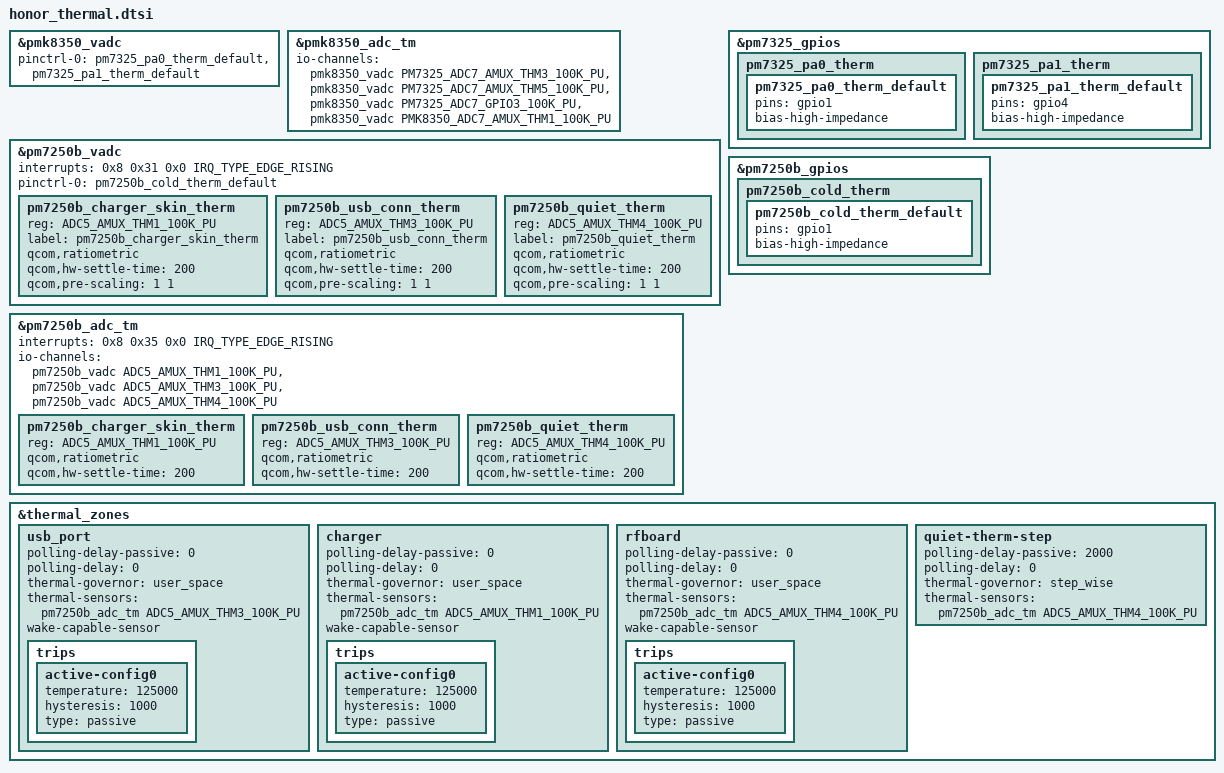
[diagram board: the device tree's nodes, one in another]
&pmk8350_vadc {
	pinctrl-names = "default";
	pinctrl-0 = <&pm7325_pa0_therm_default
				&pm7325_pa1_therm_default>;
	/delete-node/ pm8350b_quiet_therm;
	/delete-node/ pm8350b_usb_conn_therm;
	/delete-node/ pm8350b_chg_skin_therm;
};

&pmk8350_adc_tm {
	io-channels = <&pmk8350_vadc PM7325_ADC7_AMUX_THM3_100K_PU>,
			<&pmk8350_vadc PM7325_ADC7_AMUX_THM5_100K_PU>,
			<&pmk8350_vadc PM7325_ADC7_GPIO3_100K_PU>,
			<&pmk8350_vadc PMK8350_ADC7_AMUX_THM1_100K_PU>;

	/delete-node/ pm8350b_quiet_therm;
	/delete-node/ pm8350b_usb_conn_therm;
	/delete-node/ pm8350b_chg_skin_therm;
};

&pm7250b_vadc {
	interrupts = <0x8 0x31 0x0 IRQ_TYPE_EDGE_RISING>;
	pinctrl-names = "default";
	pinctrl-0 = <&pm7250b_cold_therm_default>;

	pm7250b_charger_skin_therm {
		reg = <ADC5_AMUX_THM1_100K_PU>;
		label = "pm7250b_charger_skin_therm";
		qcom,ratiometric;
		qcom,hw-settle-time = <200>;
		qcom,pre-scaling = <1 1>;
	};

	pm7250b_usb_conn_therm {
		reg = <ADC5_AMUX_THM3_100K_PU>;
		label = "pm7250b_usb_conn_therm";
		qcom,ratiometric;
		qcom,hw-settle-time = <200>;
		qcom,pre-scaling = <1 1>;
	};

	pm7250b_quiet_therm {
		reg = <ADC5_AMUX_THM4_100K_PU>;
		label = "pm7250b_quiet_therm";
		qcom,ratiometric;
		qcom,hw-settle-time = <200>;
		qcom,pre-scaling = <1 1>;
	};
};

&pm7325_gpios {
	pm7325_pa0_therm {
		pm7325_pa0_therm_default: pm7325_pa0_therm_default {
			pins = "gpio1";
			bias-high-impedance;
		};
	};

	pm7325_pa1_therm {
		pm7325_pa1_therm_default: pm7325_pa1_therm_default {
			pins = "gpio4";
			bias-high-impedance;
		};
	};
};
&pm7250b_gpios {
	pm7250b_cold_therm {
		pm7250b_cold_therm_default: pm7250b_cold_therm_default {
			pins = "gpio1";
			bias-high-impedance;
		};
	};
};

&pm7250b_adc_tm {
	interrupts = <0x8 0x35 0x0 IRQ_TYPE_EDGE_RISING>;

	io-channels = <&pm7250b_vadc ADC5_AMUX_THM1_100K_PU>,
			<&pm7250b_vadc ADC5_AMUX_THM3_100K_PU>,
			<&pm7250b_vadc ADC5_AMUX_THM4_100K_PU>;

	pm7250b_charger_skin_therm {
		reg = <ADC5_AMUX_THM1_100K_PU>;
		qcom,ratiometric;
		qcom,hw-settle-time = <200>;
	};

	pm7250b_usb_conn_therm {
		reg = <ADC5_AMUX_THM3_100K_PU>;
		qcom,ratiometric;
		qcom,hw-settle-time = <200>;
	};

	pm7250b_quiet_therm {
		reg = <ADC5_AMUX_THM4_100K_PU>;
		qcom,ratiometric;
		qcom,hw-settle-time = <200>;
	};
};

&thermal_zones {
	usb_port {
		polling-delay-passive = <0>;
		polling-delay = <0>;
		thermal-governor = "user_space";
		thermal-sensors = <&pm7250b_adc_tm ADC5_AMUX_THM3_100K_PU>;
		wake-capable-sensor;
		trips {
			active-config0 {
				temperature = <125000>;
				hysteresis = <1000>;
				type = "passive";
			};
		};
	};

	charger {
		polling-delay-passive = <0>;
		polling-delay = <0>;
		thermal-governor = "user_space";
		thermal-sensors = <&pm7250b_adc_tm ADC5_AMUX_THM1_100K_PU>;
		wake-capable-sensor;
		trips {
			active-config0 {
				temperature = <125000>;
				hysteresis = <1000>;
				type = "passive";
			};
		};
	};

	rfboard {
		polling-delay-passive = <0>;
		polling-delay = <0>;
		thermal-governor = "user_space";
		thermal-sensors = <&pm7250b_adc_tm ADC5_AMUX_THM4_100K_PU>;
		wake-capable-sensor;
		trips {
			active-config0 {
				temperature = <125000>;
				hysteresis = <1000>;
				type = "passive";
			};
		};
	};

	quiet-therm-step {
		polling-delay-passive = <2000>;
		polling-delay = <0>;
		thermal-governor = "step_wise";
		thermal-sensors = <&pm7250b_adc_tm ADC5_AMUX_THM4_100K_PU>;
	};
};
